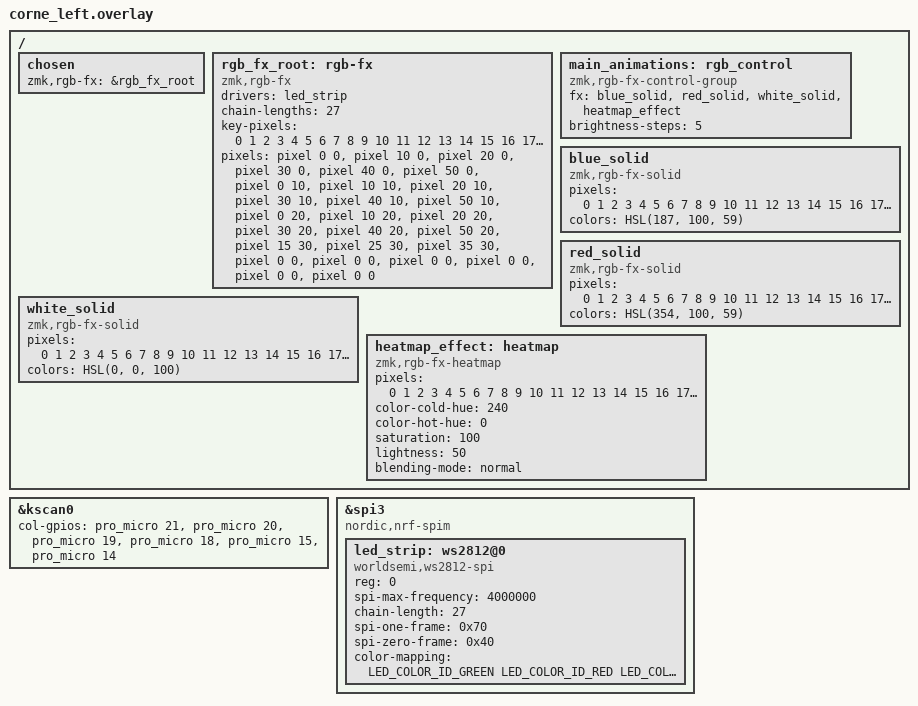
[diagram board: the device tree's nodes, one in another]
/*
 * Copyright (c) 2020 Pete Johanson
 *
 * SPDX-License-Identifier: MIT
 */

#include "corne.dtsi"
#include <dt-bindings/led/led.h>
#include <dt-bindings/zmk/rgb_fx.h>
//#include <zephyr/drivers/led_strip.h>
#include <rgb_fx.dtsi>

&kscan0 {
    col-gpios
        = <&pro_micro 21 GPIO_ACTIVE_HIGH>
        , <&pro_micro 20 GPIO_ACTIVE_HIGH>
        , <&pro_micro 19 GPIO_ACTIVE_HIGH>
        , <&pro_micro 18 GPIO_ACTIVE_HIGH>
        , <&pro_micro 15 GPIO_ACTIVE_HIGH>
        , <&pro_micro 14 GPIO_ACTIVE_HIGH>
        ;
};
&spi3 {
    compatible = "nordic,nrf-spim";
    status = "okay";
    
    led_strip: ws2812@0 {
        compatible = "worldsemi,ws2812-spi";
        reg = <0>;
        spi-max-frequency = <4000000>;
        chain-length = <27>;
        spi-one-frame = <0x70>;
        spi-zero-frame = <0x40>;
        color-mapping = <LED_COLOR_ID_GREEN LED_COLOR_ID_RED LED_COLOR_ID_BLUE>;
    };
};

/ {
    chosen {
        zmk,rgb-fx = &rgb_fx_root;
    };

    rgb_fx_root: rgb-fx {
        compatible = "zmk,rgb-fx";
        drivers = <&led_strip>;
        chain-lengths = <27>;
        
        // Map left half keys (positions 0-20) to LED indices
        // Adjust these numbers based on your actual LED wiring!
        key-pixels = <
            0 1 2 3 4 5       // Keys 0-5 (top row)
            6 7 8 9 10 11     // Keys 6-11 (middle row)
            12 13 14 15 16 17 // Keys 12-17 (bottom row)
            18 19 20          // Keys 18-20 (thumbs)
        >;
        
        // Define pixel positions (adjust x,y coordinates for your layout)
        pixels
            = <&pixel 0 0>, <&pixel 10 0>, <&pixel 20 0>, <&pixel 30 0>, <&pixel 40 0>, <&pixel 50 0>     // Top row
            , <&pixel 0 10>, <&pixel 10 10>, <&pixel 20 10>, <&pixel 30 10>, <&pixel 40 10>, <&pixel 50 10>  // Middle row
            , <&pixel 0 20>, <&pixel 10 20>, <&pixel 20 20>, <&pixel 30 20>, <&pixel 40 20>, <&pixel 50 20>  // Bottom row
            , <&pixel 15 30>, <&pixel 25 30>, <&pixel 35 30>  // Thumbs
            , <&pixel 0 0>, <&pixel 0 0>, <&pixel 0 0>, <&pixel 0 0>, <&pixel 0 0>, <&pixel 0 0>  // Extra LEDs (underglow)
        ;
    };
    
    // Animation control group
    main_animations: rgb_control {
        compatible = "zmk,rgb-fx-control-group";

        
        fx = <&blue_solid &red_solid &white_solid &heatmap_effect>;
        brightness-steps = <5>;
    };
    
    // Define your effects
    blue_solid: blue_solid {
        compatible = "zmk,rgb-fx-solid";
        pixels = <0 1 2 3 4 5 6 7 8 9 10 11 12 13 14 15 16 17 18 19 20>;
        colors = <HSL(187, 100, 59)>;
    };
    
    red_solid: red_solid {
        compatible = "zmk,rgb-fx-solid";
        pixels = <0 1 2 3 4 5 6 7 8 9 10 11 12 13 14 15 16 17 18 19 20>;
        colors = <HSL(354, 100, 59)>;
    };
    
    white_solid: white_solid {
        compatible = "zmk,rgb-fx-solid";
        pixels = <0 1 2 3 4 5 6 7 8 9 10 11 12 13 14 15 16 17 18 19 20>;
        colors = <HSL(0, 0, 100)>;
    };
    
    heatmap_effect: heatmap {
        compatible = "zmk,rgb-fx-heatmap";
        pixels = <0 1 2 3 4 5 6 7 8 9 10 11 12 13 14 15 16 17 18 19 20>;
        color-cold-hue = <240>;
        color-hot-hue = <0>;
        saturation = <100>;
        lightness = <50>;
        blending-mode = "normal";
    };
};
